# Montana register map
Vendor: ONSemiconductor; Series: Montana Series; File version: 1.0
CPU: CM33 r0p4, little endian, MPU, FPU, 3 interrupt priority bits
Registers are 32-bit, read-write, reset 0x0 unless marked. A register's access mark holds for its fields unless they carry their own. Offsets are from the block's base; [hi:lo] are bit positions.

## UART — UART Interface Configuration and Control
Base 0x40000E00
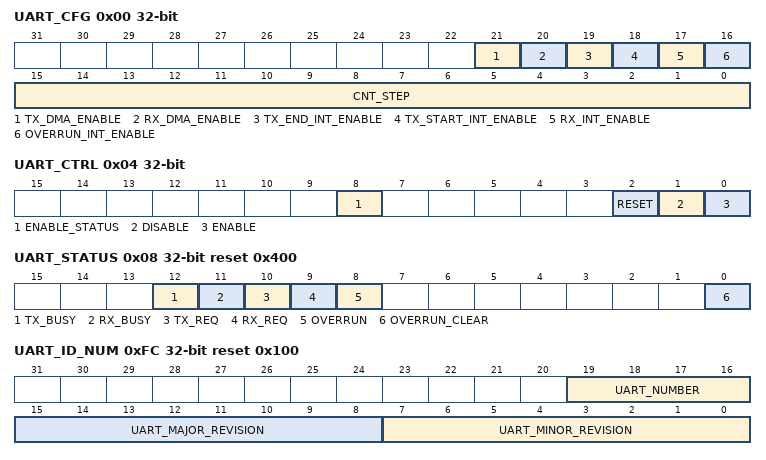
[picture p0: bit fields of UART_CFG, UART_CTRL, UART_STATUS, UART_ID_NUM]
0x00 UART_CFG — UART Configuration Register
  [21] TX_DMA_ENABLE — Enable/disable the TX DMA request
    0=UART_TX_DMA_DISABLE (No TX DMA request is generated); 1=UART_TX_DMA_ENABLE (A TX DMA request is generated when new data is requested by the UART interface)
  [20] RX_DMA_ENABLE — Enable/disable the RX DMA request
    0=UART_RX_DMA_DISABLE (No RX DMA request is generated); 1=UART_RX_DMA_ENABLE (An RX DMA request is generated when new data is received by the UART interface)
  [19] TX_END_INT_ENABLE — Enable/disable the TX end interrupt
    0=UART_TX_END_INT_DISABLE (No TX interrupt is raised); 1=UART_TX_END_INT_ENABLE (A TX interrupt is raised when data transmission by the UART interface is finished)
  [18] TX_START_INT_ENABLE — Enable/disable the TX start interrupt
    0=UART_TX_START_INT_DISABLE (No TX interrupt is raised); 1=UART_TX_START_INT_ENABLE (A TX interrupt is raised when new data is requested by the UART interface)
  [17] RX_INT_ENABLE — Enable/disable the RX interrupt
    0=UART_RX_INT_DISABLE (No RX interrupt is raised); 1=UART_RX_INT_ENABLE (An RX interrupt is raised when new data is received by the UART interface)
  [16] OVERRUN_INT_ENABLE — Enable/disable the overrun interrupt
    0=UART_OVERRUN_INT_DISABLE (No ERROR interrupt is raised when an overrun is detected); 1=UART_OVERRUN_INT_ENABLE (An ERROR interrupt is raised when an overrun occurs on the UART interface)
  [15:0] CNT_STEP — Counter step size that configures the baud rate
    0x9D4=UART_9600_BAUD (9600 baud at UARTCLK 1 MHz); 0xEBE=UART_14400_BAUD (14400 baud at UARTCLK 1 MHz); 0x13A8=UART_19200_BAUD (19200 baud at UARTCLK 1 MHz); 0x2751=UART_38400_BAUD (38400 baud at UARTCLK 1 MHz); 0x3AFA=UART_57600_BAUD (57600 baud at UARTCLK 1 MHz); 0x75F6=UART_115200_BAUD (115200 baud at UARTCLK 1 MHz); 0x7AE0=UART_120000_BAUD (120000 baud at UARTCLK 1 MHz); 0x7FFF=UART_125000_BAUD (125000 baud at UARTCLK 1 MHz)
0x04 UART_CTRL (reset mask 0x100) — UART Control Register
  [8] ENABLE_STATUS ro — UART enable status
    0=UART_STATUS_DISABLED (UART interface is disabled); 1=UART_STATUS_ENABLED (UART interface is enabled)
  [2] RESET wo — Reset the UART interface
    1=UART_RESET (Reset the UART interface)
  [1] DISABLE wo — Disable the UART interface
    1=UART_DISABLE (Disable the UART interface)
  [0] ENABLE wo — Enable the UART interface
    1=UART_ENABLE (Enable the UART interface)
0x08 UART_STATUS reset 0x400 (reset mask 0x1F00)
  [12] TX_BUSY ro — Indicate that a TX transaction is ongoing
    0=UART_TX_IDLE (No UART TX transaction is ongoing); 1=UART_TX_BUSY (UART TX transaction is ongoing)
  [11] RX_BUSY ro — Indicate that a RX transaction is ongoing
    0=UART_RX_IDLE (No UART RX transaction is ongoing); 1=UART_RX_BUSY (UART RX transaction is ongoing)
  [10] TX_REQ ro — Indicate that a TX data can be written
    0=UART_TX_NO_REQ (UART TX data has already been written); 1=UART_TX_REQ (UART TX data can be written)
  [9] RX_REQ ro — Indicate that a RX data can be read
    0=UART_RX_NO_REQ (No new UART RX data available); 1=UART_RX_REQ (New UART RX data available)
  [8] OVERRUN ro — Indicate that an overrun occurred when receiving data
    0=UART_OVERRUN_FALSE (No UART RX overrun detected); 1=UART_OVERRUN_TRUE (UART RX overrun detected)
  [0] OVERRUN_CLEAR wo — Clear the overrun status flag
    1=UART_OVERRUN_CLEAR (Clear the RX overrun status bit)
0x0C UART_TX_DATA — UART Transmit Data Register
  [7:0] TX_DATA — Transmitted data
0x10 UART_RX_DATA ro — UART Receive Data Register
  [7:0] RX_DATA — Received data
0xFC UART_ID_NUM ro reset 0x100 — UART ID number
  [19:16] UART_NUMBER — UART Instance number
  [15:8] UART_MAJOR_REVISION — UART Major Revision number
    1=UART_MAJOR_REVISION (UART revision 1.0)
  [7:0] UART_MINOR_REVISION — UART Minor Revision number
    0=UART_MINOR_REVISION (UART revision 1.0)
